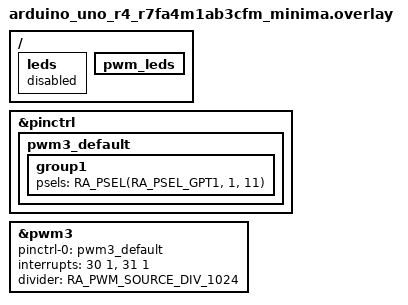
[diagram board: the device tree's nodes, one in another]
#include <zephyr/dt-bindings/pwm/pwm.h>
#include <zephyr/dt-bindings/pwm/ra_pwm.h>

/ {
	leds {
		status = "disabled";
	};

	pwm_leds {
		status = "okay";
	};
};

&pinctrl {
	pwm3_default: pwm3_default {
		group1 {
			/* GTIOC3A */
			psels = <RA_PSEL(RA_PSEL_GPT1, 1, 11)>;
		};
	};
};

&pwm3 {
	pinctrl-0 = <&pwm3_default>;
	pinctrl-names = "default";
	interrupts = <30 1>, <31 1>;
	interrupt-names = "gtioca", "overflow";
	status = "okay";
	divider = <RA_PWM_SOURCE_DIV_1024>;
};
